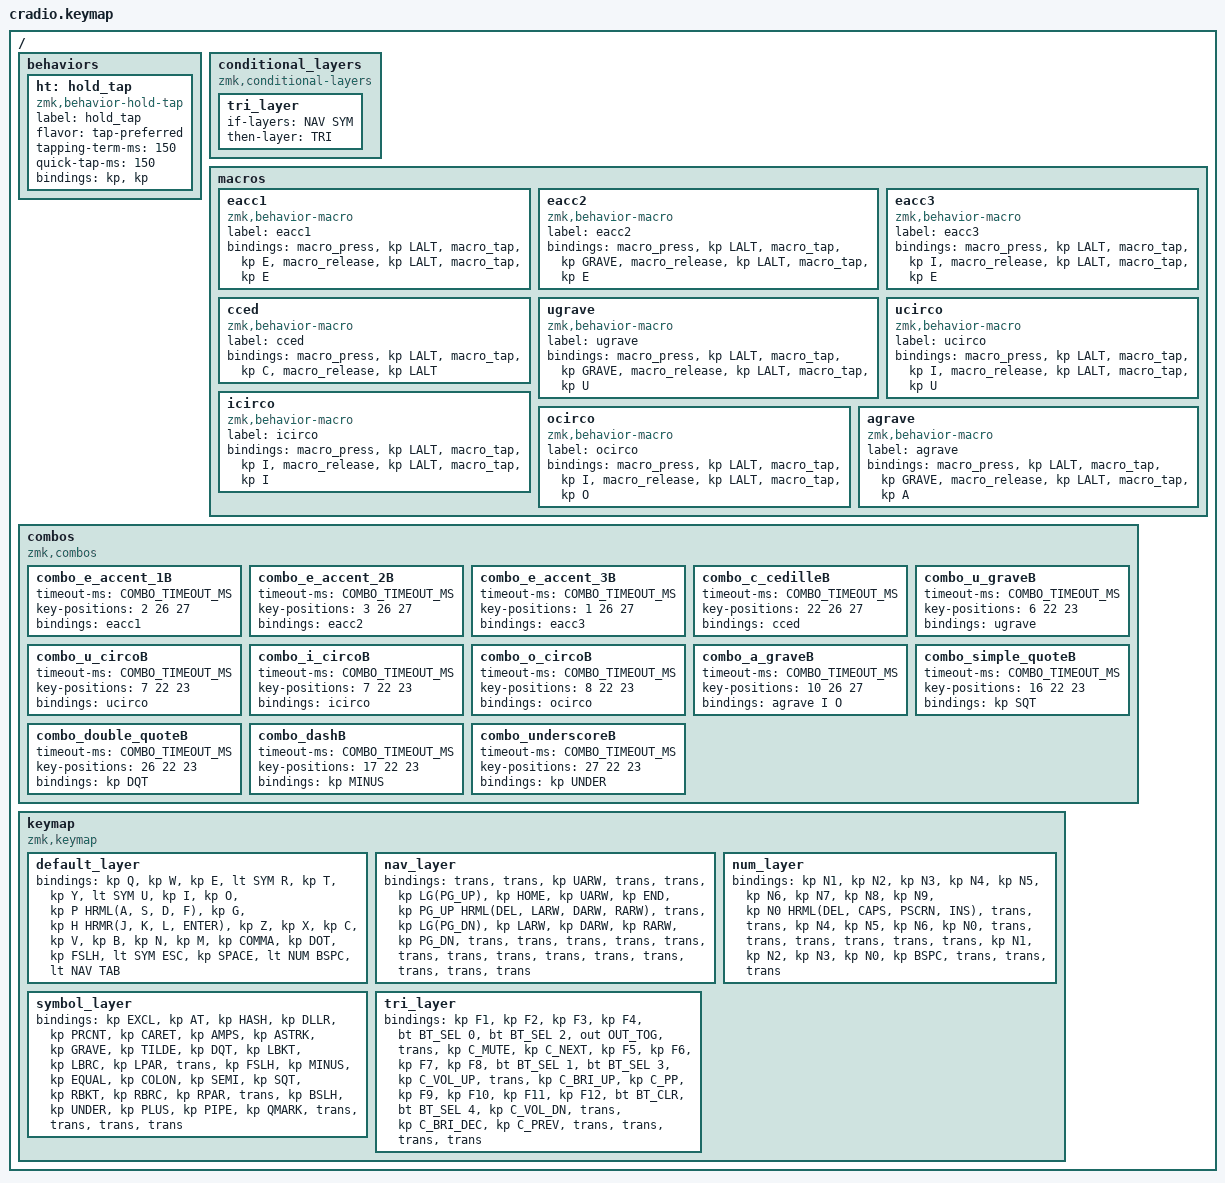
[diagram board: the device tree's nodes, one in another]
// Copyright (c) 2022 The ZMK Contributors
// SPDX-License-Identifier: MIT

#include <behaviors.dtsi>
#include <dt-bindings/zmk/keys.h>
#include <dt-bindings/zmk/bt.h>
#include <dt-bindings/zmk/outputs.h>

// Home row mods macro
#define HRML(k1, k2,k3,k4) &ht LSHIFT k1 &ht LALT k2  &ht LCTRL k3  &ht LGUI k4
#define HRMR(k1,k2,k3,k4) &ht RGUI k1  &ht RCTRL k2  &ht RALT k3 &ht RSHIFT k4
#define WHRML(k2,k3,k4) &ht LALT k2  &ht LGUI k3  &ht LCTRL k4
#define WHRMR(k1,k2,k3) &ht RCTRL k1  &ht RGUI k2  &ht RALT k3

#define MAC 0
#define NAV 1
#define NUM 2
#define SYM 3
#define TRI 4

#define COMBO_LAYER_TIMEOUT_MS 30
#define COMBO_TIMEOUT_MS 40

/ {
    behaviors 
    {
        ht: hold_tap {
            label = "hold_tap";
            compatible = "zmk,behavior-hold-tap";
            #binding-cells = <2>;
            flavor = "tap-preferred";
            tapping-term-ms = <150>;
            quick-tap-ms = <150>;
            bindings = <&kp>, <&kp>;
        };

    };

    conditional_layers {
        compatible = "zmk,conditional-layers";
        tri_layer {
            if-layers = <NAV SYM>;
            then-layer = <TRI>;
        };
    };

    macros {
        eacc1: eacc1 {
            label = "eacc1";
            compatible = "zmk,behavior-macro";
            #binding-cells = <0>;
            bindings
                = <&macro_press &kp LALT>
                , <&macro_tap &kp E>
                , <&macro_release &kp LALT>
                , <&macro_tap &kp E>
                ;
        };

        eacc2: eacc2 {
            label = "eacc2";
            compatible = "zmk,behavior-macro";
            #binding-cells = <0>;
            bindings
                = <&macro_press &kp LALT>
                , <&macro_tap &kp GRAVE>
                , <&macro_release &kp LALT>
                , <&macro_tap &kp E>
                ; 
        };
 
         eacc3: eacc3 {
            label = "eacc3";
            compatible = "zmk,behavior-macro";
            #binding-cells = <0>;
            bindings
                = <&macro_press &kp LALT>
                , <&macro_tap &kp I>
                , <&macro_release &kp LALT>
                , <&macro_tap &kp E> 
                ; 
        };
 
        cced: cced {
            label = "cced";
            compatible = "zmk,behavior-macro";
            #binding-cells = <0>;
            bindings
                = <&macro_press &kp LALT>
                , <&macro_tap &kp C>
                , <&macro_release &kp LALT>                 
                ; 
        };

 
        ugrave: ugrave {
            label = "ugrave";
            compatible = "zmk,behavior-macro";
            #binding-cells = <0>;
            bindings
                = <&macro_press &kp LALT>
                , <&macro_tap &kp GRAVE>
                , <&macro_release &kp LALT>
                , <&macro_tap &kp U>
                ; 
        };

        ucirco: ucirco {
            label = "ucirco";
            compatible = "zmk,behavior-macro";
            #binding-cells = <0>;
            bindings
                = <&macro_press &kp LALT>
                , <&macro_tap &kp I>
                , <&macro_release &kp LALT>
                , <&macro_tap &kp U> 
                ; 
        };

        icirco: icirco {
            label = "icirco";
            compatible = "zmk,behavior-macro";
            #binding-cells = <0>;
            bindings
                = <&macro_press &kp LALT>
                , <&macro_tap &kp I>
                , <&macro_release &kp LALT>
                , <&macro_tap &kp I> 
                ; 
        };  

        ocirco: ocirco {
            label = "ocirco";
            compatible = "zmk,behavior-macro";
            #binding-cells = <0>;
            bindings
                = <&macro_press &kp LALT>
                , <&macro_tap &kp I>
                , <&macro_release &kp LALT>
                , <&macro_tap &kp O> 
                ; 
        };  

        agrave: agrave {
            label = "agrave";
            compatible = "zmk,behavior-macro";
            #binding-cells = <0>;
            bindings
                = <&macro_press &kp LALT>
                , <&macro_tap &kp GRAVE>
                , <&macro_release &kp LALT>
                , <&macro_tap &kp A> 
                ; 
        };
    };
    
    combos {
        compatible = "zmk,combos";
        
//        combo_e_accent_1 {
//            timeout-ms = <COMBO_TIMEOUT_MS>;
//            key-positions = <2 3 26>;
//            bindings = <&eacc1>;
//        };

        combo_e_accent_1B {
            timeout-ms = <COMBO_TIMEOUT_MS>;
            key-positions = <2 26 27>;
            bindings = <&eacc1>;
        };
      
//        combo_e_accent_2 {
//            timeout-ms = <COMBO_TIMEOUT_MS>;
//            key-positions = <1 2 26>;
//            bindings = <&eacc2>;
//        };

        combo_e_accent_2B {
            timeout-ms = <COMBO_TIMEOUT_MS>;
            key-positions = <3 26 27>;
            bindings = <&eacc2>;
        };

//        combo_e_accent_3 {
//            timeout-ms = <COMBO_TIMEOUT_MS>;
//            key-positions = <0 2 26>;
//            bindings = <&eacc3>;
//        };

        combo_e_accent_3B {
            timeout-ms = <COMBO_TIMEOUT_MS>;
            key-positions = <1 26 27>;
            bindings = <&eacc3>;
        };

//        combo_c_cedille {
//            timeout-ms = <COMBO_TIMEOUT_MS>;
//            key-positions = <22 23 26>;
//            bindings = <&cced>;
//        };

        combo_c_cedilleB {
            timeout-ms = <COMBO_TIMEOUT_MS>;
            key-positions = <22 26 27>;
            bindings = <&cced>;
        };

//        combo_u_grave {
//            timeout-ms = <COMBO_TIMEOUT_MS>;
//            key-positions = <6 7 23>;
//            bindings = <&ugrave>;
//        };

        combo_u_graveB {
            timeout-ms = <COMBO_TIMEOUT_MS>;
            key-positions = <6 22 23>;
            bindings = <&ugrave>;
        };

//        combo_u_circo {
//            timeout-ms = <COMBO_TIMEOUT_MS>;
//            key-positions = <6 9 23>;
//            bindings = <&ucirco>;
//        };

        combo_u_circoB {
            timeout-ms = <COMBO_TIMEOUT_MS>;
            key-positions = <7 22 23>;
            bindings = <&ucirco>;
        };

//        combo_i_circo {
//            timeout-ms = <COMBO_TIMEOUT_MS>;
//            key-positions = <7 9 23>;
//            bindings = <&icirco>;
//        };

        combo_i_circoB {
            timeout-ms = <COMBO_TIMEOUT_MS>;
            key-positions = <7 22 23>;
            bindings = <&icirco>;
        };

//         combo_o_circo {
//            timeout-ms = <COMBO_TIMEOUT_MS>;
//            key-positions = <8 9 23>;
//            bindings = <&ocirco>;
//       };

         combo_o_circoB {
            timeout-ms = <COMBO_TIMEOUT_MS>;
            key-positions = <8 22 23>;
            bindings = <&ocirco>;
        };

//        combo_a_grave {
//            timeout-ms = <COMBO_TIMEOUT_MS>;
//            key-positions = <10 11 26>;
//            bindings = <&agrave I O>;
//        };

        combo_a_graveB{
            timeout-ms = <COMBO_TIMEOUT_MS>;
            key-positions = <10 26 27>;
            bindings = <&agrave I O>;
        };

//        combo_simple_quote {
//            timeout-ms = <COMBO_TIMEOUT_MS>;
//            key-positions = <16 17 23>;
//            bindings = <&kp SQT>;
//        };

        combo_simple_quoteB {
            timeout-ms = <COMBO_TIMEOUT_MS>;
            key-positions = <16 22 23>;
            bindings = <&kp SQT>;
        };

//        combo_double_quote {
//            timeout-ms = <COMBO_TIMEOUT_MS>;
//            key-positions = <26 27 23>;
//            bindings = <&kp DQT>;
//        };

        combo_double_quoteB {
            timeout-ms = <COMBO_TIMEOUT_MS>;
            key-positions = <26 22 23>;
            bindings = <&kp DQT>;
        };

//        combo_dash {
//            timeout-ms = <COMBO_TIMEOUT_MS>;
//            key-positions = <16 18 23>;
//            bindings = <&kp MINUS>;
//        };

        combo_dashB {
            timeout-ms = <COMBO_TIMEOUT_MS>;
            key-positions = <17 22 23>;
            bindings = <&kp MINUS>;
        };

//        combo_underscore {
//            timeout-ms = <COMBO_TIMEOUT_MS>;
//            key-positions = <26 28 23>;
//            bindings = <&kp UNDER>;
//        };

        combo_underscoreB {
            timeout-ms = <COMBO_TIMEOUT_MS>;
            key-positions = <27 22 23>;
            bindings = <&kp UNDER>;
        };
    };

    keymap {
        compatible = "zmk,keymap";
        default_layer {
            bindings = <
        //╭──────────┬──────────┬──────────┬──────────┬──────────╮   ╭──────────┬──────────┬──────────┬──────────┬──────────╮
        //│  Q       │  W       │  E       │  R       │  T       │   │  Y       │  U       │  I       │  O       │  P       │
            &kp Q      &kp W      &kp E      &lt SYM R   &kp T          &kp Y   &lt SYM U      &kp I      &kp O      &kp P
        //├──────────┼──────────┼──────────┼──────────┼──────────┤   ├──────────┼──────────┼──────────┼──────────┼──────────┤
        //│  A       │  S       │  D       │  F       │  G       │   │  H       │  J       │  K       │  L       │   ENTER  │
            HRML(A,        S,         D,         F)     &kp G          &kp H      HRMR(J,        K,           L,     ENTER)
        //├──────────┼──────────┼──────────┼──────────┼──────────┤   ├──────────┼──────────┼──────────┼──────────┼──────────┤
        //│  Z       │  X       │  C       │  V       │  B       │   │  N       │  M       │ , <      │ . >      │ / ?      │
            &kp Z      &kp X      &kp C      &kp V      &kp B          &kp N      &kp M      &kp COMMA  &kp DOT    &kp FSLH
        //╰──────────┴──────────┴──────────┼──────────┼──────────┤   ├──────────┼──────────┼──────────┴──────────┴──────────╯
                                           &lt SYM ESC  &kp SPACE     &lt NUM BSPC   &lt NAV TAB
        //                                 ╰──────────┴──────────╯   ╰──────────┴──────────╯
            >;
        };

        nav_layer {
            bindings = <
        //╭──────────┬──────────┬──────────┬──────────┬──────────╮   ╭──────────┬──────────┬──────────┬──────────┬──────────╮
        //│          │          │  UP      │          │          │   │ SCROLLUP │  HOME     │ UP       │  END     │  PAGE UP│
            &trans    &trans     &kp UARW     &trans     &trans        &kp LG(PG_UP) &kp HOME &kp UARW  &kp END    &kp PG_UP
        //├──────────┼──────────┼──────────┼──────────┼──────────┤   ├──────────┼──────────┼──────────┼──────────┼──────────┤
        //│ DELETE   │ LEFT     │ DOWN     │  RIGHT   │          |   | SCROLLDN │ LEFT     │ DOWN     │ RIGHT    │ PAGE DOWN│
            HRML(DEL,  LARW,      DARW,     RARW)   &trans           &kp LG(PG_DN) &kp LARW &kp DARW   &kp RARW   &kp PG_DN
        //├──────────┼──────────┼──────────┼──────────┼──────────┤   ├──────────┼──────────┼──────────┼──────────┼──────────┤
        //│          │          │          │          │          │   │          │          │          │          |          │
            &trans    &trans     &trans     &trans      &trans           &trans   &trans      &trans   &trans      &trans 
        //╰──────────┴──────────┴──────────┼──────────┼──────────┤   ├──────────┼──────────┼──────────┴──────────┴──────────╯
                                             &trans     &trans          &trans     &trans
        //                                 ╰──────────┴──────────╯   ╰──────────┴──────────╯
            >;
        };

        num_layer {
            bindings = <
        //╭──────────┬──────────┬──────────┬──────────┬──────────╮   ╭──────────┬──────────┬──────────┬──────────┬──────────╮
        //│ 1        │  2       │  3       │  4       │  5       │   │ 6        │ 7        │ 8       │ 9        │   0      │
            &kp N1    &kp N2     &kp N3     &kp N4     &kp N5          &kp N6    &kp N7     &kp N8    &kp N9      &kp N0
        //├──────────┼──────────┼──────────┼──────────┼──────────┤   ├──────────┼──────────┼──────────┼──────────┼──────────┤
        //│ DELETE   │ CapsLock │ PrintSc  │  INSERT  │          |   |          │ 4        │ 5        │ 6        │  0       │  
            HRML(DEL,  CAPS,      PSCRN,     INS)       &trans          &trans    &kp N4   &kp N5       &kp N6    &kp N0  
        //├──────────┼──────────┼──────────┼──────────┼──────────┤   ├──────────┼──────────┼──────────┼──────────┼──────────┤
        //│          │          │          │          │          │   │          │ 1        │ 2        │ 3        │  0      │
            &trans    &trans     &trans     &trans      &trans           &trans   &kp N1    &kp N2      &kp N3     &kp N0 
        //╰──────────┴──────────┴──────────┼──────────┼──────────┤   ├──────────┼──────────┼──────────┴──────────┴──────────╯
                                             &kp BSPC     &trans          &trans     &trans
        //                                 ╰──────────┴──────────╯   ╰──────────┴──────────╯
            >;
        };

         

        symbol_layer {
            bindings = <
        //╭──────────┬──────────┬──────────┬──────────┬──────────╮   ╭──────────┬──────────┬──────────┬──────────┬──────────╮
        //│  !       │  @       │  #       │  $       │  %       │   │  ^       │  &       │  *       │  `       │  ~       │
            &kp EXCL   &kp AT     &kp HASH   &kp DLLR   &kp PRCNT      &kp CARET  &kp AMPS   &kp ASTRK  &kp GRAVE   &kp TILDE
        //├──────────┼──────────┼──────────┼──────────┼──────────┤   ├──────────┼──────────┼──────────┼──────────┼──────────┤
        //│  "       │  [       │  {       │  (       │          │   │   /      │  -       │  =       │     :    │  ;       │
            &kp DQT  &kp LBKT   &kp LBRC   &kp LPAR   &trans         &kp FSLH   &kp MINUS  &kp EQUAL  &kp COLON   &kp SEMI
        //├──────────┼──────────┼──────────┼──────────┼──────────┤   ├──────────┼──────────┼──────────┼──────────┼──────────┤
        //│  '       │  ]       │  }       │  )       │          │   │    \     │  _       │  +       │  │       │   ?      │
            &kp SQT     &kp RBKT   &kp RBRC   &kp RPAR   &trans         &kp BSLH   &kp UNDER  &kp PLUS   &kp PIPE  &kp QMARK
        //╰──────────┴──────────┴──────────┼──────────┼──────────┤   ├──────────┼──────────┼──────────┴──────────┴──────────╯
                                             &trans     &trans         &trans     &trans
        //                                 ╰──────────┴──────────╯   ╰──────────┴──────────╯
            >;
        };
        tri_layer {
            bindings = <
        //╭──────────┬──────────┬──────────┬───────────┬────────────╮   ╭────────────┬────────────┬──────────┬───────────┬──────────╮
        //│  F1      │  F2      │  F3      │  F4       │ PROFILE 0  │   │ PROFILE 2  │ TOGGLEOUT  │          │ VOL MUTE  │ NEXTSONG │
            &kp F1     &kp F2     &kp F3     &kp F4     &bt BT_SEL 0     &bt BT_SEL 2  &out OUT_TOG  &trans   &kp C_MUTE  &kp C_NEXT
        //├──────────┼──────────┼──────────┼───────────┼────────────┤   ├────────────┼────────────┼──────────┼───────────┼──────────┤
        //│  F5      │  F6      │  F7      │  F8       │ PROFILE 1  │   │ PROFILE 3  │ VOL UP     │          | INC BRIGHT│PAUSEMUSIC│
            &kp F5     &kp F6     &kp F7     &kp F8     &bt BT_SEL 1     &bt BT_SEL 3  &kp C_VOL_UP  &trans   &kp C_BRI_UP &kp C_PP
        //├──────────┼──────────┼──────────┼───────────┼────────────┤   ├────────────┼────────────┼──────────┼───────────┼──────────┤
        //│  F9      │  F10     │  F11     │  F12      │  CLEAR BT  │   │ PROFILE 4  │  VOL DOWN  │          | DEC BRIGHT │ PREVSONG │
            &kp F9     &kp F10    &kp F11    &kp F12     &bt BT_CLR      &bt BT_SEL 4 &kp C_VOL_DN  &trans   &kp C_BRI_DEC  &kp C_PREV
        //╰──────────┴──────────┴──────────┼───────────┼────────────┤   ├────────────┼────────────┼──────────┴───────────┴──────────╯
                                                &trans     &trans         &trans     &trans
        //                                  ╰───────────┴──────────╯   ╰──────────┴────────────╯
            >;
        };
    };
};
